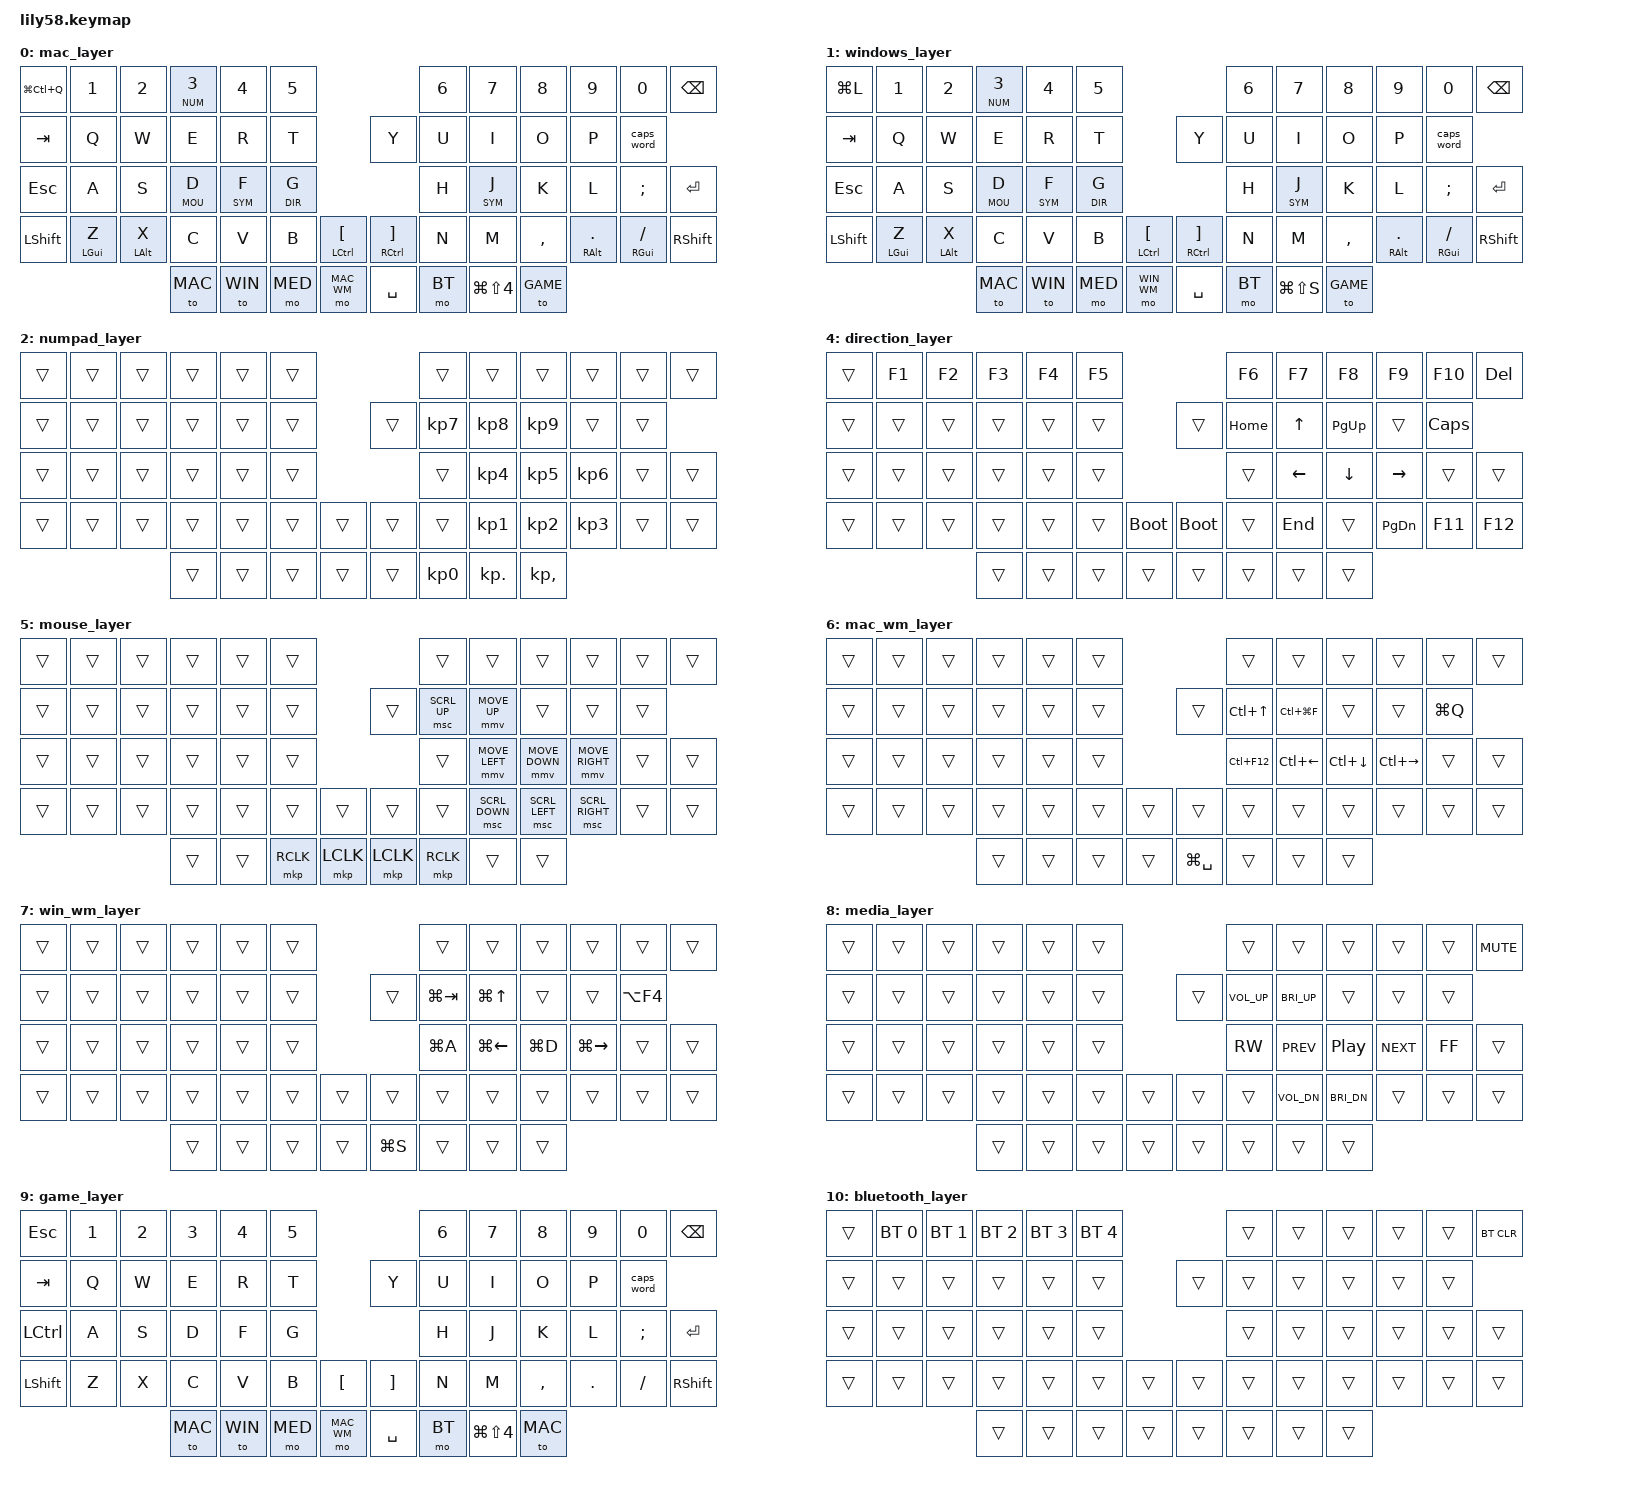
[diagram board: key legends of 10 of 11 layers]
/*
 * Copyright (c) 2020 The ZMK Contributors
 *
 * SPDX-License-Identifier: MIT
 */

#include <dt-bindings/zmk/mouse.h>
#include <behaviors.dtsi>
#include <dt-bindings/zmk/keys.h>
#include <dt-bindings/zmk/pointing.h>
#include <dt-bindings/zmk/bt.h>

// Layer indices

#define MAC     0
#define WIN     1
#define NUM     2
#define SYM     3
#define DIR     4
#define MOU     5
#define MAC_WM  6
#define WIN_WM  7
#define MED     8
#define GAME    9
#define BT     10

/ {

    keymap {
        compatible = "zmk,keymap";

        mac_layer {
            // ┌──────────┬─────┬─────┬──────────┬─────┬─────┐                 ┌─────┬─────┬─────┬─────┬─────┬──────┐
            // │  LOCK    │  1  │  2  │ 3/numpad │  4  │  5  │                 │  6  │  7  │  8  │  9  │  0  │ BSPC │
            // ├──────────┼─────┼─────┼──────────┼─────┼─────┤                 ├─────┼─────┼─────┼─────┼─────┼──────┤
            // │   TAB    │  Q  │  W  │    E     │  R  │  T  │                 │  Y  │  U  │  I  │  O  │  P  │ CAPS │
            // │          │     │     │          │     │     │                 │     │     │     │     │     │ WORD │
            // ├──────────┼─────┼─────┼──────────┼─────┼─────┤                 ├─────┼─────┼─────┼─────┼─────┼──────┤
            // │   ESC    │  A  │  S  │  D/mouse │F/sym│G/dir│                 │  H  │J/sym│  K  │  L  │  ;  │ ENT  │
            // ├──────────┼─────┼─────┼──────────┼─────┼─────┼──────┐  ┌──────┼─────┼─────┼─────┼─────┼─────┼──────┤
            // │  LSHFT   │Z/⌘  │X/⌥  │    C    │  V  │  B  │ [/⌃  │  │ ]/⌃  │  N  │  M  │  ,  │ ./⌥ │ //⌘ │RSHFT │
            // └──────────┴─────┴─────┼──────────┼─────┼─────┼──────┤  ├──────┼─────┼─────┼─────┼─────┴─────┴──────┘
            //                        │   →mac   │→win │ MED │  WM  │  │ SPC  │     │ ⌘⇧4 │     │
            //                        └──────────┴─────┴─────┴──────┘  └──────┴─────┴─────┴─────┘

            bindings = <
&kp LG(LC(Q))  &kp N1      &kp N2      &lt NUM N3   &kp N4   &kp N5                            &kp N6  &kp N7          &kp N8           &kp N9        &kp N0         &kp BSPC
&kp TAB        &kp Q       &kp W       &kp E        &kp R    &kp T                             &kp Y   &kp U           &kp I            &kp O         &kp P          &caps_word
&kp ESC        &kp A       &kp S       &lt MOU D    &lt SYM F    &lt DIR G                         &kp H   &lt SYM J       &kp K            &kp L         &kp SEMI       &kp ENTER
&kp LSHFT      &mt LGUI Z  &mt LALT X  &kp C        &kp V    &kp B    &mt LCTRL LBKT  &mt RCTRL RBKT   &kp N   &kp M           &kp COMMA        &mt RALT DOT  &mt RGUI FSLH  &kp RSHFT
                                        &to MAC      &to WIN  &mo MED  &mo MAC_WM      &kp SPACE  &mo BT  &kp LG(LS(N4))  &to GAME
            >;

            sensor-bindings = <&inc_dec_kp C_VOL_UP C_VOL_DN>;
        };

        windows_layer {
            // Identical to mac_layer but screenshot uses Win+Shift+S

            bindings = <
&kp LG(L)    &kp N1      &kp N2      &lt NUM N3        &kp N4   &kp N5                            &kp N6  &kp N7         &kp N8           &kp N9        &kp N0         &kp BSPC
&kp TAB      &kp Q       &kp W       &kp E        &kp R    &kp T                             &kp Y   &kp U          &kp I            &kp O         &kp P          &caps_word
&kp ESC      &kp A       &kp S       &lt MOU D        &lt SYM F    &lt DIR G                             &kp H   &lt SYM J          &kp K            &kp L         &kp SEMI       &kp ENTER
&kp LSHFT    &mt LGUI Z  &mt LALT X  &kp C        &kp V    &kp B    &mt LCTRL LBKT      &mt RCTRL RBKT   &kp N   &kp M          &kp COMMA        &mt RALT DOT  &mt RGUI FSLH  &kp RSHFT
                                     &to MAC      &to WIN  &mo MED  &mo WIN_WM          &kp SPACE  &mo BT  &kp LG(LS(S))  &to GAME
            >;

            sensor-bindings = <&inc_dec_kp C_VOL_UP C_VOL_DN>;
        };

        numpad_layer {
            // ┌───────┬───────┬───────┬───────┬───────┬───────┐                 ┌───────┬───────┬───────┬───────┬───────┬───────┐
            // │       │       │       │  [3]  │       │       │                 │       │   7   │   8   │   9   │       │       │
            // ├───────┼───────┼───────┼───────┼───────┼───────┤                 ├───────┼───────┼───────┼───────┼───────┼───────┤
            // │       │       │       │       │       │       │                 │       │   4   │   5   │   6   │       │       │
            // ├───────┼───────┼───────┼───────┼───────┼───────┤                 ├───────┼───────┼───────┼───────┼───────┼───────┤
            // │       │       │       │       │       │       │                 │       │   1   │   2   │   3   │       │       │
            // ├───────┼───────┼───────┼───────┼───────┼───────┼───────┐  ┌─────┼───────┼───────┼───────┼───────┼───────┼───────┤
            // │       │       │       │       │       │       │       │  │     │       │       │       │       │       │       │
            // └───────┴───────┴───────┼───────┼───────┼───────┼───────┤  ├─────┼───────┼───────┼───────┼───────┴───────┴───────┘
            //                         │       │       │       │       │  │     │   0   │   .   │   ,   │
            //                         └───────┴───────┴───────┴───────┘  └─────┴───────┴───────┴───────┘

            bindings = <
&trans  &trans  &trans  &trans  &trans  &trans                    &trans     &trans      &trans        &trans     &trans  &trans
&trans  &trans  &trans  &trans  &trans  &trans                    &trans     &kp KP_N7   &kp KP_N8     &kp KP_N9  &trans  &trans
&trans  &trans  &trans  &trans  &trans  &trans                    &trans     &kp KP_N4   &kp KP_N5     &kp KP_N6  &trans  &trans
&trans  &trans  &trans  &trans  &trans  &trans  &trans    &trans  &trans     &kp KP_N1   &kp KP_N2     &kp KP_N3  &trans  &trans
                        &trans  &trans  &trans  &trans    &trans  &kp KP_N0  &kp KP_DOT  &kp KP_COMMA
            >;
        };

        symbols_layer {
            // ┌───────┬───────┬───────┬───────┬───────┬───────┐                 ┌───────┬───────┬───────┬───────┬───────┬───────┐
            // │       │       │       │   &   │   {   │       │                 │       │   }   │   |   │       │       │       │
            // ├───────┼───────┼───────┼───────┼───────┼───────┤                 ├───────┼───────┼───────┼───────┼───────┼───────┤
            // │       │   !   │   @   │   #   │  [F]  │   %   │                 │   ^   │  [J]  │   *   │   `   │   ~   │       │
            // ├───────┼───────┼───────┼───────┼───────┼───────┤                 ├───────┼───────┼───────┼───────┼───────┼───────┤
            // │       │       │       │       │   '   │   \   │       │  │       │   /   │   "   │       │       │       │       │
            // └───────┴───────┴───────┼───────┼───────┼───────┼───────┤  ├───────┼───────┼───────┼───────┼───────┴───────┴───────┘
            //                         │       │       │       │       │  │       │       │       │       │
            //                         └───────┴───────┴───────┴───────┘  └───────┴───────┴───────┴───────┘

            bindings = <
&trans  &trans    &trans  &trans    &trans    &trans                          &trans     &trans    &trans     &trans     &trans     &trans
&trans  &trans    &trans  &kp AMPS  &kp LBRC  &kp MINUS                       &kp PLUS   &kp RBRC  &kp PIPE   &trans     &trans     &trans
&trans  &kp EXCL  &kp AT  &kp HASH  &kp LPAR  &kp PRCNT                       &kp CARET  &kp RPAR  &kp ASTRK  &kp GRAVE  &kp TILDE  &trans
&trans  &trans    &trans  &trans    &kp SQT   &kp BSLH   &kp EQUAL    &trans  &kp FSLH   &kp DQT
            >;
        };

        direction_layer {
            // ┌───────┬─────┬─────┬─────┬─────┬─────┐                       ┌─────┬─────┬─────┬─────┬──────┬─────┐
            // │       │ F1  │ F2  │ F3  │ F4  │ F5  │                       │ F6  │ F7  │ F8  │ F9  │ F10  │ DEL │
            // ├───────┼─────┼─────┼─────┼─────┼─────┤                       ├─────┼─────┼─────┼─────┼──────┼─────┤
            // │       │     │     │     │     │     │                       │     │HOME │ UP  │PGUP │      │CAPS │
            // ├───────┼─────┼─────┼─────┼─────┼─────┤                       ├─────┼─────┼─────┼─────┼──────┼─────┤
            // │       │     │     │     │     │[G]  │                       │     │LEFT │DOWN │RIGHT│      │     │
            // ├───────┼─────┼─────┼─────┼─────┼─────┼──────────┐  ┌────────┼─────┼─────┼─────┼─────┼──────┼─────┤
            // │       │     │     │     │     │     │BOOTLOADER│  │BOOTLOAD│     │ END │     │PGDN │ F11  │ F12 │
            // └───────┴─────┴─────┼─────┼─────┼─────┼──────────┤  ├────────┼─────┼─────┼─────┼─────┴──────┴─────┘
            //                     │     │     │     │          │  │        │     │     │     │
            //                     └─────┴─────┴─────┴──────────┘  └────────┴─────┴─────┴─────┘

            bindings = <
&trans  &kp F1  &kp F2  &kp F3  &kp F4  &kp F5                              &kp F6  &kp F7    &kp F8    &kp F9     &kp F10  &kp DEL
&trans  &trans  &trans  &trans  &trans  &trans                              &trans  &kp HOME  &kp UP    &kp PG_UP  &trans   &kp CAPS
&trans  &trans  &trans  &trans  &trans  &trans                              &trans  &kp LEFT  &kp DOWN  &kp RIGHT  &trans   &trans
&trans  &trans  &trans  &trans  &trans  &trans  &bootloader    &bootloader  &trans  &kp END   &trans    &kp PG_DN  &kp F11  &kp F12
                        &trans  &trans  &trans  &trans         &trans       &trans  &trans    &trans
            >;
        };

        mouse_layer {
            // ┌────────┬──────┬──────┬──────┬──────┬──────┐                 ┌──────┬─────────┬──────────┬──────┬──────┬──────┐
            // │        │      │      │      │      │      │                 │      │ SCRL_UP │  MV_UP   │      │      │      │
            // ├────────┼──────┼──────┼──────┼──────┼──────┤                 ├──────┼─────────┼──────────┼──────┼──────┼──────┤
            // │        │      │      │ [D]  │      │      │                 │      │ MV_LEFT │  MV_DOWN │MV_RT │      │      │
            // ├────────┼──────┼──────┼──────┼──────┼──────┤                 ├──────┼─────────┼──────────┼──────┼──────┼──────┤
            // │        │      │      │      │      │      │                 │      │ SCRL_DN │  SCRL_L  │SCRL_R│      │      │
            // ├────────┼──────┼──────┼──────┼──────┼──────┼──────┐  ┌──────┼──────┼─────────┼──────────┼──────┼──────┼──────┤
            // │        │      │      │      │      │      │      │  │      │      │         │          │      │      │      │
            // └────────┴──────┴──────┼──────┼──────┼──────┼──────┤  ├──────┼──────┼─────────┼──────────┼──────┴──────┴──────┘
            //                        │      │      │ RCLK │ LCLK │  │ LCLK │ RCLK │         │          │
            //                        └──────┴──────┴──────┴──────┘  └──────┴──────┴─────────┴──────────┘

            bindings = <
&trans  &trans  &trans  &trans  &trans  &trans                             &trans     &trans          &trans          &trans           &trans  &trans
&trans  &trans  &trans  &trans  &trans  &trans                             &trans     &msc SCRL_UP    &mmv MOVE_UP    &trans           &trans  &trans
&trans  &trans  &trans  &trans  &trans  &trans                             &trans     &mmv MOVE_LEFT  &mmv MOVE_DOWN  &mmv MOVE_RIGHT  &trans  &trans
&trans  &trans  &trans  &trans  &trans  &trans     &trans       &trans     &trans     &msc SCRL_DOWN  &msc SCRL_LEFT  &msc SCRL_RIGHT  &trans  &trans
                        &trans  &trans  &mkp RCLK  &mkp LCLK    &mkp LCLK  &mkp RCLK  &trans          &trans
            >;
        };

        mac_wm_layer {
            // ┌───────┬───────┬───────┬───────┬───────┬───────┐                 ┌───────┬──────────┬──────────┬───────┬───────┬───────┐
            // │       │       │       │       │       │       │                 │       │ MC (⌃↑)  │ FULL(⌃⌘F)│       │       │       │
            // ├───────┼───────┼───────┼───────┼───────┼───────┤                 ├───────┼──────────┼──────────┼───────┼───────┼───────┤
            // │       │       │       │       │       │       │                 │ NOTIF │ SPC← (⌃←)│ EXPO(⌃↓) │SPC→(⌃→)│      │       │
            // ├───────┼───────┼───────┼───────┼───────┼───────┤                 ├───────┼──────────┼──────────┼───────┼───────┼───────┤
            // │       │       │       │       │       │       │       │  │       │       │          │          │       │       │       │
            // └───────┴───────┴───────┼───────┼───────┼───────┼───────┤  ├───────┼──────┼──────────┼──────────┼───────┴───────┴───────┘
            //                         │       │       │       │[WM]   │  │SPTLGT │       │          │          │
            //                         └───────┴───────┴───────┴───────┘  └───────┴───────┴──────────┴──────────┘
            // Note: NOTIF (H) requires a custom shortcut set in System Settings → Keyboard → Shortcuts → Mission Control

            bindings = <
&trans  &trans  &trans  &trans  &trans  &trans                           &trans       &trans        &trans         &trans         &trans  &trans
&trans  &trans  &trans  &trans  &trans  &trans                           &trans       &kp LC(UP)    &kp LC(LG(F))  &trans         &trans  &kp LG(Q)
&trans  &trans  &trans  &trans  &trans  &trans                           &kp LC(F12)  &kp LC(LEFT)  &kp LC(DOWN)   &kp LC(RIGHT)  &trans  &trans
&trans  &trans  &trans  &trans  &trans  &trans  &trans    &trans         &trans       &trans        &trans         &trans         &trans  &trans
                        &trans  &trans  &trans  &trans    &kp LG(SPACE)  &trans       &trans        &trans
            >;
        };

        win_wm_layer {
            // ┌───────┬───────┬───────┬───────┬───────┬───────┐                 ┌───────┬──────────┬──────────┬───────┬───────┬────────┐
            // │       │       │       │       │       │       │                 │       │ TASKVIEW │  MAX(⊞↑) │       │       │ ALT+F4 │
            // ├───────┼───────┼───────┼───────┼───────┼───────┤                 ├───────┼──────────┼──────────┼───────┼───────┼────────┤
            // │       │       │       │       │       │       │                 │ ACT.C │ TILE←(⊞←)│ SHOW DSK │TILE→(⊞→)│     │        │
            // ├───────┼───────┼───────┼───────┼───────┼───────┤                 ├───────┼──────────┼──────────┼───────┼───────┼────────┤
            // │       │       │       │       │       │       │       │  │       │       │          │          │       │       │        │
            // └───────┴───────┴───────┼───────┼───────┼───────┼───────┤  ├───────┼──────┼──────────┼──────────┼───────┴───────┴────────┘
            //                         │       │       │       │[WM]   │  │SEARCH │       │          │          │
            //                         └───────┴───────┴───────┴───────┘  └───────┴───────┴──────────┴──────────┘

            bindings = <
&trans  &trans  &trans  &trans  &trans  &trans                       &trans     &trans        &trans      &trans         &trans  &trans
&trans  &trans  &trans  &trans  &trans  &trans                       &trans     &kp LG(TAB)   &kp LG(UP)  &trans         &trans  &kp LA(F4)
&trans  &trans  &trans  &trans  &trans  &trans                       &kp LG(A)  &kp LG(LEFT)  &kp LG(D)   &kp LG(RIGHT)  &trans  &trans
&trans  &trans  &trans  &trans  &trans  &trans  &trans    &trans     &trans     &trans        &trans      &trans         &trans  &trans
                        &trans  &trans  &trans  &trans    &kp LG(S)  &trans     &trans        &trans
            >;
        };

        media_layer {
            // ┌───────┬───────┬───────┬───────┬───────┬───────┐                 ┌───────┬───────┬───────┬───────┬───────┬───────┐
            // │       │       │       │       │       │       │                 │       │ VOL + │ BRI + │       │       │ MUTE  │
            // ├───────┼───────┼───────┼───────┼───────┼───────┤                 ├───────┼───────┼───────┼───────┼───────┼───────┤
            // │       │       │       │       │       │       │                 │  REW  │ PREV  │ PLAY  │ NEXT  │  FF   │       │
            // ├───────┼───────┼───────┼───────┼───────┼───────┤                 ├───────┼───────┼───────┼───────┼───────┼───────┤
            // │       │       │       │       │       │       │       │  │       │       │ VOL - │ BRI - │       │       │       │
            // └───────┴───────┴───────┼───────┼───────┼───────┼───────┤  ├───────┼──────┼───────┼───────┼───────┴───────┴───────┘
            //                         │       │       │ [MED] │       │  │       │       │       │       │
            //                         └───────┴───────┴───────┴───────┘  └───────┴───────┴───────┴───────┘

            bindings = <
&trans  &trans  &trans  &trans  &trans  &trans                    &trans    &trans        &trans        &trans      &trans    &kp C_MUTE
&trans  &trans  &trans  &trans  &trans  &trans                    &trans    &kp C_VOL_UP  &kp C_BRI_UP  &trans      &trans    &trans
&trans  &trans  &trans  &trans  &trans  &trans                    &kp C_RW  &kp C_PREV    &kp C_PP      &kp C_NEXT  &kp C_FF  &trans
&trans  &trans  &trans  &trans  &trans  &trans  &trans    &trans  &trans    &kp C_VOL_DN  &kp C_BRI_DN  &trans      &trans    &trans
                        &trans  &trans  &trans  &trans    &trans  &trans    &trans        &trans
            >;
        };

        game_layer {
            // Mac layer but with plain 3/D/F/G/J — no hold behaviours that cause misfires in games

            bindings = <
&kp ESC    &kp N1  &kp N2  &kp N3   &kp N4   &kp N5                            &kp N6  &kp N7          &kp N8     &kp N9   &kp N0    &kp BSPC
&kp TAB    &kp Q   &kp W   &kp E    &kp R    &kp T                             &kp Y   &kp U           &kp I      &kp O    &kp P     &caps_word
&kp LCTRL  &kp A   &kp S   &kp D    &kp F    &kp G                             &kp H   &kp J           &kp K      &kp L    &kp SEMI  &kp ENTER
&kp LSHFT  &kp Z   &kp X   &kp C    &kp V    &kp B    &kp LBKT      &kp RBKT   &kp N   &kp M           &kp COMMA  &kp DOT  &kp FSLH  &kp RSHFT
                           &to MAC  &to WIN  &mo MED  &mo MAC_WM    &kp SPACE  &mo BT  &kp LG(LS(N4))  &to MAC
            >;

            sensor-bindings = <&inc_dec_kp C_VOL_UP C_VOL_DN>;
        };

        bluetooth_layer {
            // ┌───────┬──────────┬──────────┬──────────┬──────────┬──────────┐                 ┌───────┬───────┬───────┬───────┬───────┬────────┐
            // │       │  BT  1   │  BT  2   │  BT  3   │  BT  4   │  BT  5   │                 │       │       │       │       │       │ BT CLR │
            // ├───────┼──────────┼──────────┼──────────┼──────────┼──────────┤                 ├───────┼───────┼───────┼───────┼───────┼────────┤
            // │       │          │          │          │          │          │                 │       │       │       │       │       │        │
            // ├───────┼──────────┼──────────┼──────────┼──────────┼──────────┤                 ├───────┼───────┼───────┼───────┼───────┼────────┤
            // │       │          │          │          │          │          │       │  │       │       │       │       │       │       │        │
            // └───────┴──────────┴──────────┼──────────┼──────────┼──────────┼───────┤  ├───────┼───────┼───────┼───────┼───────┴───────┴────────┘
            //                               │          │          │          │       │  │       │ [BT]  │       │       │
            //                               └──────────┴──────────┴──────────┴───────┘  └───────┴───────┴───────┴───────┘

            bindings = <
&trans  &bt BT_SEL 0  &bt BT_SEL 1  &bt BT_SEL 2  &bt BT_SEL 3  &bt BT_SEL 4              &trans  &trans  &trans  &trans  &trans  &bt BT_CLR
&trans  &trans        &trans        &trans        &trans        &trans                    &trans  &trans  &trans  &trans  &trans  &trans
&trans  &trans        &trans        &trans        &trans        &trans                    &trans  &trans  &trans  &trans  &trans  &trans
&trans  &trans        &trans        &trans        &trans        &trans  &trans    &trans  &trans  &trans  &trans  &trans  &trans  &trans
                                    &trans        &trans        &trans  &trans    &trans  &trans  &trans  &trans
            >;
        };
    };
};
